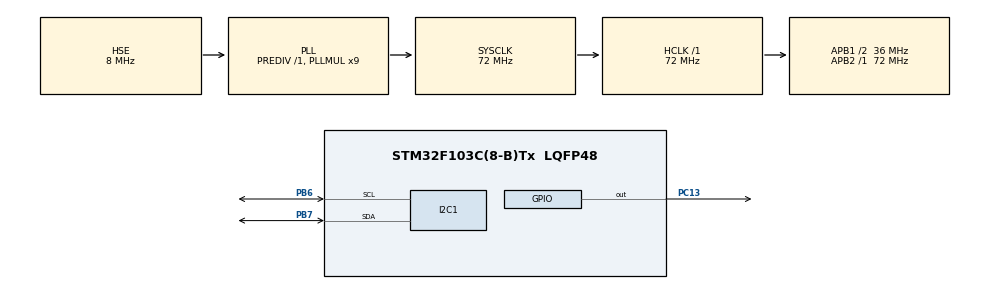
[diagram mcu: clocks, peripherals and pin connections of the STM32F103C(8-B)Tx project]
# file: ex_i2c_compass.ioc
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I2C1.I2C_Mode=I2C_Standard
Mcu.Family=STM32F1
Mcu.Name=STM32F103C(8-B)Tx
Mcu.Package=LQFP48
NVIC.PriorityGroup=NVIC_PRIORITYGROUP_4
PA13.Mode=Serial_Wire
PA13.Signal=SYS_JTMS-SWDIO
PA14.Mode=Serial_Wire
PA14.Signal=SYS_JTCK-SWCLK
PB6.Mode=I2C
PB6.Signal=I2C1_SCL
PB7.Mode=I2C
PB7.Signal=I2C1_SDA
PC13-TAMPER-RTC.Signal=GPIO_Output
PD0-OSC_IN.Mode=HSE-External-Oscillator
PD0-OSC_IN.Signal=RCC_OSC_IN
PD1-OSC_OUT.Mode=HSE-External-Oscillator
PD1-OSC_OUT.Signal=RCC_OSC_OUT
ProjectManager.HeapSize=0x200
ProjectManager.StackSize=0x400
ProjectManager.TargetToolchain=STM32CubeIDE
RCC.AHBFreq_Value=72000000
RCC.APB1CLKDivider=RCC_HCLK_DIV2
RCC.APB1Freq_Value=36000000
RCC.APB1TimFreq_Value=72000000
RCC.APB2Freq_Value=72000000
RCC.APB2TimFreq_Value=72000000
RCC.HCLKFreq_Value=72000000
RCC.PLLMUL=RCC_PLL_MUL9
RCC.PLLSourceVirtual=RCC_PLLSOURCE_HSE
RCC.SYSCLKFreq_VALUE=72000000
RCC.SYSCLKSource=RCC_SYSCLKSOURCE_PLLCLK
RCC.USBFreq_Value=72000000
board=custom

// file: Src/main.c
/* USER CODE BEGIN Header */
/**
  ******************************************************************************
  * @file           : main.c
  * @brief          : Main program body
  ******************************************************************************
  * @attention
  *
  * <h2><center>&copy; Copyright (c) 2019 STMicroelectronics.
  * All rights reserved.</center></h2>
  *
  * This software component is licensed by ST under BSD 3-Clause license,
  * the "License"; You may not use this file except in compliance with the
  * License. You may obtain a copy of the License at:
  *                        opensource.org/licenses/BSD-3-Clause
  *
  ******************************************************************************
  */
/* USER CODE END Header */

#include "main.h"

I2C_HandleTypeDef hi2c1;

void SystemClock_Config(void);
static void MX_GPIO_Init(void);
static void MX_I2C1_Init(void);

#define HMC5883l_ADDRESS (0x1E << 1)
#define HMC5883l_Enable_A (0x70)
#define HMC5883l_Enable_B (0xA0)
#define HMC5883l_MR (0x00)

#define HMC5883l_ADD_DATAX_MSB (0x03)
#define HMC5883l_ADD_DATAX_LSB (0x04)
#define HMC5883l_ADD_DATAZ_MSB (0x05)
#define HMC5883l_ADD_DATAZ_LSB (0x06)
#define HMC5883l_ADD_DATAY_MSB (0x07)
#define HMC5883l_ADD_DATAY_LSB (0x08)
// SUM (MSB + LSB) DEFINE
#define HMC5883l_ADD_DATAX_MSB_MULTI (HMC5883l_ADD_DATAX_MSB | 0x80)
#define HMC5883l_ADD_DATAY_MSB_MULTI (HMC5883l_ADD_DATAY_MSB | 0x80)
#define HMC5883l_ADD_DATAZ_MSB_MULTI (HMC5883l_ADD_DATAZ_MSB | 0x80)
uint8_t i2cBuffer[8];
uint8_t DataX[2];
uint16_t Xaxis = 0;
uint8_t DataY[2];
uint16_t Yaxis = 0;
uint8_t DataZ[2];
uint16_t Zaxis = 0;
int main(void)
{
  /* USER CODE BEGIN 1 */
	uint8_t RegSettingA = HMC5883l_Enable_A;
	uint8_t RegSettingB = HMC5883l_Enable_B;
	uint8_t RegSettingMR = HMC5883l_MR;
	Xaxis = 0;
	Yaxis = 0;
	Zaxis = 0;
  /* USER CODE END 1 */

  /* MCU Configuration--------------------------------------------------------*/

  /* Reset of all peripherals, Initializes the Flash interface and the Systick. */
  HAL_Init();

  /* Configure the system clock */
  SystemClock_Config();

  /* Initialize all configured peripherals */
  MX_GPIO_Init();
  MX_I2C1_Init();
  /* USER CODE BEGIN 2 */

  HAL_I2C_Mem_Write(&hi2c1, HMC5883l_ADDRESS, 0x00 , 1, &RegSettingA , 1, 100);
  HAL_I2C_Mem_Write(&hi2c1, HMC5883l_ADDRESS, 0x01 , 1, &RegSettingB , 1, 100);
  HAL_I2C_Mem_Write(&hi2c1, HMC5883l_ADDRESS, 0x02 , 1, &RegSettingMR , 1, 100);

  /* USER CODE END 2 */

  /* Infinite loop */
  while (1)
  {

	  // RECEIVE X_axis
	  HAL_I2C_Mem_Read(&hi2c1,HMC5883l_ADDRESS+1,HMC5883l_ADD_DATAX_MSB_MULTI,1,DataX,2,100);
	  Xaxis = ((DataX[1]<<8) | DataX[0])/390.f;
	  // RECEIVE Y_axis
	  HAL_I2C_Mem_Read(&hi2c1,HMC5883l_ADDRESS+1,HMC5883l_ADD_DATAY_MSB_MULTI,1,DataY,2,100);
	  Yaxis = ((DataY[1]<<8) | DataY[0])/390.f;
	  // RECEIVE Z_axis
	  HAL_I2C_Mem_Read(&hi2c1,HMC5883l_ADDRESS+1,HMC5883l_ADD_DATAZ_MSB_MULTI,1,DataZ,2,100);
	  Zaxis = ((DataZ[1]<<8) | DataZ[0])/390.f;
  }
}

void SystemClock_Config(void)
{
  RCC_OscInitTypeDef RCC_OscInitStruct = {0};
  RCC_ClkInitTypeDef RCC_ClkInitStruct = {0};

  /** Initializes the CPU, AHB and APB busses clocks
  */
  RCC_OscInitStruct.OscillatorType = RCC_OSCILLATORTYPE_HSE;
  RCC_OscInitStruct.HSEState = RCC_HSE_ON;
  RCC_OscInitStruct.HSEPredivValue = RCC_HSE_PREDIV_DIV1;
  RCC_OscInitStruct.HSIState = RCC_HSI_ON;
  RCC_OscInitStruct.PLL.PLLState = RCC_PLL_ON;
  RCC_OscInitStruct.PLL.PLLSource = RCC_PLLSOURCE_HSE;
  RCC_OscInitStruct.PLL.PLLMUL = RCC_PLL_MUL9;
  if (HAL_RCC_OscConfig(&RCC_OscInitStruct) != HAL_OK)
  {
    Error_Handler();
  }
  /** Initializes the CPU, AHB and APB busses clocks
  */
  RCC_ClkInitStruct.ClockType = RCC_CLOCKTYPE_HCLK|RCC_CLOCKTYPE_SYSCLK
                              |RCC_CLOCKTYPE_PCLK1|RCC_CLOCKTYPE_PCLK2;
  RCC_ClkInitStruct.SYSCLKSource = RCC_SYSCLKSOURCE_PLLCLK;
  RCC_ClkInitStruct.AHBCLKDivider = RCC_SYSCLK_DIV1;
  RCC_ClkInitStruct.APB1CLKDivider = RCC_HCLK_DIV2;
  RCC_ClkInitStruct.APB2CLKDivider = RCC_HCLK_DIV1;

  if (HAL_RCC_ClockConfig(&RCC_ClkInitStruct, FLASH_LATENCY_2) != HAL_OK)
  {
    Error_Handler();
  }
}

static void MX_I2C1_Init(void)
{

  hi2c1.Instance = I2C1;
  hi2c1.Init.ClockSpeed = 100000;
  hi2c1.Init.DutyCycle = I2C_DUTYCYCLE_2;
  hi2c1.Init.OwnAddress1 = 0;
  hi2c1.Init.AddressingMode = I2C_ADDRESSINGMODE_7BIT;
  hi2c1.Init.DualAddressMode = I2C_DUALADDRESS_DISABLE;
  hi2c1.Init.OwnAddress2 = 0;
  hi2c1.Init.GeneralCallMode = I2C_GENERALCALL_DISABLE;
  hi2c1.Init.NoStretchMode = I2C_NOSTRETCH_DISABLE;
  if (HAL_I2C_Init(&hi2c1) != HAL_OK)
  {
    Error_Handler();
  }

}

static void MX_GPIO_Init(void)
{
  GPIO_InitTypeDef GPIO_InitStruct = {0};

  /* GPIO Ports Clock Enable */
  __HAL_RCC_GPIOC_CLK_ENABLE();
  __HAL_RCC_GPIOD_CLK_ENABLE();
  __HAL_RCC_GPIOA_CLK_ENABLE();
  __HAL_RCC_GPIOB_CLK_ENABLE();

  /*Configure GPIO pin Output Level */
  HAL_GPIO_WritePin(GPIOC, GPIO_PIN_13, GPIO_PIN_RESET);

  /*Configure GPIO pin : PC13 */
  GPIO_InitStruct.Pin = GPIO_PIN_13;
  GPIO_InitStruct.Mode = GPIO_MODE_OUTPUT_PP;
  GPIO_InitStruct.Pull = GPIO_NOPULL;
  GPIO_InitStruct.Speed = GPIO_SPEED_FREQ_LOW;
  HAL_GPIO_Init(GPIOC, &GPIO_InitStruct);

}

void Error_Handler(void)
{
}

/************************ (C) COPYRIGHT STMicroelectronics *****END OF FILE****/
